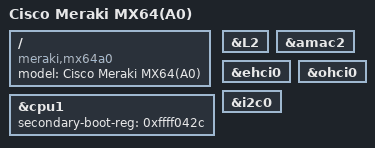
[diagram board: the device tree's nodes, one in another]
// SPDX-License-Identifier: GPL-2.0-or-later OR MIT
/*
 * Device Tree Bindings for Cisco Meraki MX64(A0).
 *
 * Copyright (C) 2021 Matthew Hagan <mnhagan88@gmail.com>
 */

/dts-v1/;

#include "bcm958625-mx64x.dtsi"

/ {
	model = "Cisco Meraki MX64(A0)";
	compatible = "meraki,mx64a0", "brcm,bcm58625", "brcm,nsp";
};

&cpu1 {
	secondary-boot-reg = <0xffff042c>;
};

&L2 {
	/delete-property/ arm,io-coherent;
	/delete-property/ prefetch-data;
	/delete-property/ prefetch-instr;
};

&amac2 {
	/delete-property/ dma-coherent;
};

&ehci0 {
	/delete-property/ dma-coherent;
};

&ohci0 {
	/delete-property/ dma-coherent;
};

&i2c0 {
	/delete-property/ dma-coherent;
};
